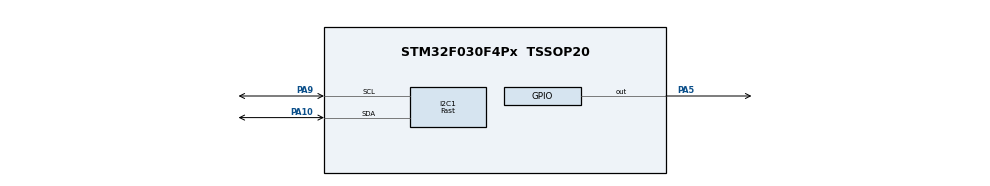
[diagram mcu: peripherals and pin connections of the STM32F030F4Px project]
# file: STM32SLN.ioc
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I2C1.I2C_Speed_Mode=I2C_Fast
I2C1.Timing=0x0010020A
Mcu.Family=STM32F0
Mcu.Name=STM32F030F4Px
Mcu.Package=TSSOP20
NVIC.I2C1_IRQn=true\:0\:0\:false\:false\:true\:true\:true\:true
PA10.Mode=I2C
PA10.Signal=I2C1_SDA
PA13.Mode=Serial_Wire
PA13.Signal=SYS_SWDIO
PA14.Mode=Serial_Wire
PA14.Signal=SYS_SWCLK
PA5.Signal=GPIO_Output
PA9.Mode=I2C
PA9.Signal=I2C1_SCL
ProjectManager.HeapSize=0x200
ProjectManager.StackSize=0x400
ProjectManager.TargetToolchain=CMake
board=custom

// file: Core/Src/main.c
/* USER CODE BEGIN Header */
/**
  ******************************************************************************
  * @file           : main.c
  * @brief          : Main program body
  ******************************************************************************
  * @attention
  *
  * Copyright (c) 2026 STMicroelectronics.
  * All rights reserved.
  *
  * This software is licensed under terms that can be found in the LICENSE file
  * in the root directory of this software component.
  * If no LICENSE file comes with this software, it is provided AS-IS.
  *
  ******************************************************************************
  */
/* USER CODE END Header */
#include "main.h"

/* USER CODE BEGIN Includes */
#include "MPU6050.h"
/* USER CODE END Includes */

I2C_HandleTypeDef hi2c1;

/* USER CODE BEGIN PV */
MPU6050 mpu6050;
/* USER CODE END PV */

void SystemClock_Config(void);
static void MX_GPIO_Init(void);
static void MX_I2C1_Init(void);

int main(void)
{

  /* MCU Configuration--------------------------------------------------------*/

  /* Reset of all peripherals, Initializes the Flash interface and the Systick. */
  HAL_Init();

  /* Configure the system clock */
  SystemClock_Config();

  /* Initialize all configured peripherals */
  MX_GPIO_Init();
  MX_I2C1_Init();
  /* USER CODE BEGIN 2 */
  STM32_MPU6050_Binding(&mpu6050,0x68);
  ACCELERATION_DATA_t acceleration;

  uint8_t who_am_i = 0;
  // 采用 HAL 库最稳妥的阻塞模式读 0x75 寄存器
  HAL_StatusTypeDef test_status = HAL_I2C_Mem_Read(&hi2c1, (0x68 << 1), 0x75, I2C_MEMADD_SIZE_8BIT, &who_am_i, 1, 100);
  __NOP();

  /* USER CODE END 2 */

  /* Infinite loop */
  while (1)
  {

    /* USER CODE BEGIN 3 */

  MPU6050_Read_Data(&mpu6050, &acceleration);
  for (volatile int i = 0; i < 30000; i++) {

  }
    HAL_GPIO_TogglePin(GPIOA, GPIO_PIN_5);
  HAL_Delay(1000);

  }
  /* USER CODE END 3 */
}

void SystemClock_Config(void)
{
  RCC_OscInitTypeDef RCC_OscInitStruct = {0};
  RCC_ClkInitTypeDef RCC_ClkInitStruct = {0};
  RCC_PeriphCLKInitTypeDef PeriphClkInit = {0};

  /** Initializes the RCC Oscillators according to the specified parameters
  * in the RCC_OscInitTypeDef structure.
  */
  RCC_OscInitStruct.OscillatorType = RCC_OSCILLATORTYPE_HSI;
  RCC_OscInitStruct.HSIState = RCC_HSI_ON;
  RCC_OscInitStruct.HSICalibrationValue = RCC_HSICALIBRATION_DEFAULT;
  RCC_OscInitStruct.PLL.PLLState = RCC_PLL_NONE;
  if (HAL_RCC_OscConfig(&RCC_OscInitStruct) != HAL_OK)
  {
    Error_Handler();
  }

  /** Initializes the CPU, AHB and APB buses clocks
  */
  RCC_ClkInitStruct.ClockType = RCC_CLOCKTYPE_HCLK|RCC_CLOCKTYPE_SYSCLK
                              |RCC_CLOCKTYPE_PCLK1;
  RCC_ClkInitStruct.SYSCLKSource = RCC_SYSCLKSOURCE_HSI;
  RCC_ClkInitStruct.AHBCLKDivider = RCC_SYSCLK_DIV1;
  RCC_ClkInitStruct.APB1CLKDivider = RCC_HCLK_DIV1;

  if (HAL_RCC_ClockConfig(&RCC_ClkInitStruct, FLASH_LATENCY_0) != HAL_OK)
  {
    Error_Handler();
  }
  PeriphClkInit.PeriphClockSelection = RCC_PERIPHCLK_I2C1;
  PeriphClkInit.I2c1ClockSelection = RCC_I2C1CLKSOURCE_HSI;
  if (HAL_RCCEx_PeriphCLKConfig(&PeriphClkInit) != HAL_OK)
  {
    Error_Handler();
  }
}

static void MX_I2C1_Init(void)
{

  hi2c1.Instance = I2C1;
  hi2c1.Init.Timing = 0x0010020A;
  hi2c1.Init.OwnAddress1 = 0;
  hi2c1.Init.AddressingMode = I2C_ADDRESSINGMODE_7BIT;
  hi2c1.Init.DualAddressMode = I2C_DUALADDRESS_DISABLE;
  hi2c1.Init.OwnAddress2 = 0;
  hi2c1.Init.OwnAddress2Masks = I2C_OA2_NOMASK;
  hi2c1.Init.GeneralCallMode = I2C_GENERALCALL_DISABLE;
  hi2c1.Init.NoStretchMode = I2C_NOSTRETCH_DISABLE;
  if (HAL_I2C_Init(&hi2c1) != HAL_OK)
  {
    Error_Handler();
  }

  /** Configure Analogue filter
  */
  if (HAL_I2CEx_ConfigAnalogFilter(&hi2c1, I2C_ANALOGFILTER_ENABLE) != HAL_OK)
  {
    Error_Handler();
  }

  /** Configure Digital filter
  */
  if (HAL_I2CEx_ConfigDigitalFilter(&hi2c1, 0) != HAL_OK)
  {
    Error_Handler();
  }

}

static void MX_GPIO_Init(void)
{
  GPIO_InitTypeDef GPIO_InitStruct = {0};

  /* GPIO Ports Clock Enable */
  __HAL_RCC_GPIOA_CLK_ENABLE();

  /*Configure GPIO pin Output Level */
  HAL_GPIO_WritePin(GPIOA, GPIO_PIN_5, GPIO_PIN_RESET);

  /*Configure GPIO pin : PA5 */
  GPIO_InitStruct.Pin = GPIO_PIN_5;
  GPIO_InitStruct.Mode = GPIO_MODE_OUTPUT_PP;
  GPIO_InitStruct.Pull = GPIO_NOPULL;
  GPIO_InitStruct.Speed = GPIO_SPEED_FREQ_LOW;
  HAL_GPIO_Init(GPIOA, &GPIO_InitStruct);

}

void Error_Handler(void)
{
  __disable_irq();
  while (1)
  {
  }
}
